# apollo3p register map
Vendor: Ambiq Micro; Series: Apollo; File version: 1.0
CPU: CM4 r1p0, little endian, MPU, FPU, I-cache, D-cache, VTOR, ITCM, DTCM, 3 interrupt priority bits, 0 interrupts
Registers are 32-bit, read-write, reset 0x0 unless marked. A register's access mark holds for its fields unless they carry their own. Offsets are from the block's base; [hi:lo] are bit positions.

## RTC — Real Time Clock
Base 0x40004200
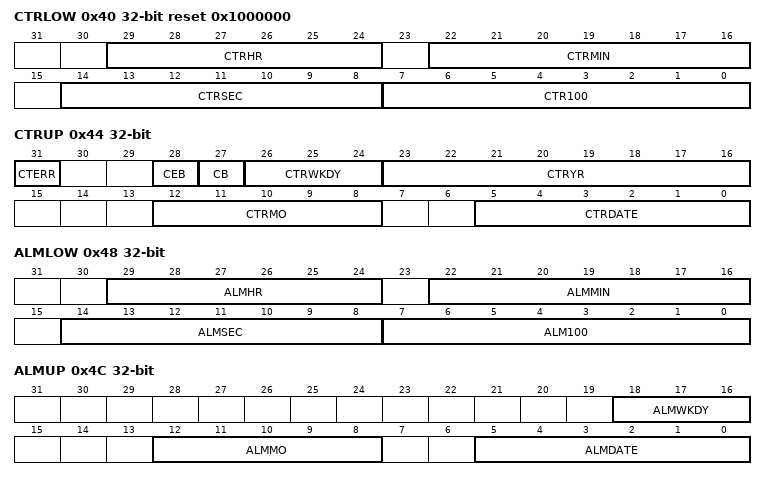
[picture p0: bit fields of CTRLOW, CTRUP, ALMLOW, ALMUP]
0x40 CTRLOW reset 0x1000000 — This counter contains the values for hour, minutes, seconds and 100ths of a second Counter.
  [29:24] CTRHR — Hours Counter
  [22:16] CTRMIN — Minutes Counter
  [14:8] CTRSEC — Seconds Counter
  [7:0] CTR100 — 100ths of a second Counter
0x44 CTRUP — This register contains the day, month and year information. It contains which day in the week, and the century as well. The information of the century can also be derived from the year information. The 31st bit contains the error bit. See description in the register bit for condition when error is triggered.
  [31] CTERR — Counter read error status. Error is triggered when software reads the lower word of the counters, and fails to read the upper counter within 1/100 second. This is because when the lower counter is read, the upper counter is held off from incrementing until it is read so that the full time stamp can be read.
    0=NOERR (No read error occurred); 1=RDERR (Read error occurred)
  [28] CEB — Century Enable Bit.
    0=DIS (Disable the Century bit from changing); 1=EN (Enable the Century bit to change)
  [27] CB — Century Bit. This bit will be toggled when the Years register rolls over from 99 to 00 if the CEB bit is a 1. CB=0 assumes the century it 19xx or 21xx, and CB=1 assumes it is 20xx for leap year calculations.
    0=Century is 2000s; 1=1900_2100 (Century is 1900s/2100s)
  [26:24] CTRWKDY — Weekdays Counter
  [23:16] CTRYR — Years Counter
  [12:8] CTRMO — Months Counter
  [5:0] CTRDATE — Date Counter
0x48 ALMLOW — This register is the Alarm settings for hours, minutes, second and 1/100th seconds settings.
  [29:24] ALMHR — Hours Alarm
  [22:16] ALMMIN — Minutes Alarm
  [14:8] ALMSEC — Seconds Alarm
  [7:0] ALM100 — 100ths of a second Alarm
0x4C ALMUP — This register is the alarm settings for week, month and day.
  [18:16] ALMWKDY — Weekdays Alarm
  [12:8] ALMMO — Months Alarm
  [5:0] ALMDATE — Date Alarm
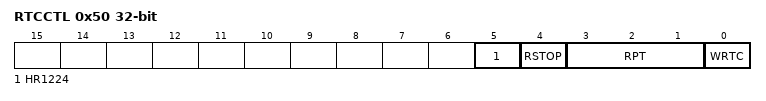
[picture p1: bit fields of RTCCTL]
0x50 RTCCTL — This is the register control for the RTC module. It sets the 12 or 24 hours mode, enables counter writes and sets the alarm repeat interval.
  [5] HR1224 — Hours Counter mode
    0=24HR (Hours in 24 hour mode); 1=12HR (Hours in 12 hour mode)
  [4] RSTOP — RTC input clock control
    0=RUN (Allow the RTC input clock to run); 1=STOP (Stop the RTC input clock)
  [3:1] RPT — Alarm repeat interval
    0=DIS (Alarm interrupt disabled); 1=YEAR (Interrupt every year); 2=MONTH (Interrupt every month); 3=WEEK (Interrupt every week); 4=DAY (Interrupt every day); 5=HR (Interrupt every hour); 6=MIN (Interrupt every minute); 7=SEC (Interrupt every second/10th/100th)
  [0] WRTC — Counter write control
    0=DIS (Counter writes are disabled); 1=EN (Counter writes are enabled)
0x100 INTEN — Set bits in this register to allow this module to generate the corresponding interrupt.
  [0] ALM — RTC Alarm interrupt
0x104 INTSTAT — Read bits from this register to discover the cause of a recent interrupt.
  [0] ALM — RTC Alarm interrupt
0x108 INTCLR — Write a 1 to a bit in this register to clear the interrupt status associated with that bit.
  [0] ALM — RTC Alarm interrupt
0x10C INTSET — Write a 1 to a bit in this register to instantly generate an interrupt from this module. (Generally used for testing purposes).
  [0] ALM — RTC Alarm interrupt

## SCARD — Serial ISO7816
Base 0x40080000
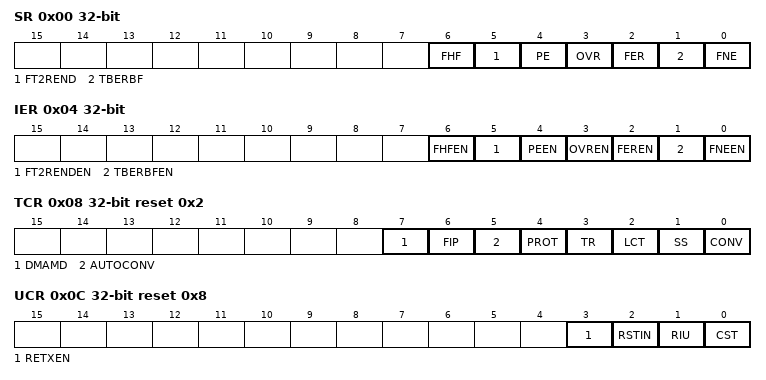
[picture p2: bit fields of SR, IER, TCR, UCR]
0x00 SR — ISO7816 interrupt status
  [6] FHF — FIFO Half Full.
    1=HALFFULL (FIFO is half full.)
  [5] FT2REND — TX to RX finished.
    1=CMPL (TX to RX completed.); 0=NOTCMPL (TX to RX not completed.)
  [4] PE — Parity Error.
    1=PEERR (Parity error.); 0=PENONE (No parity error.)
  [3] OVR — RX FIFO overflow.
    1=RXOVR (RX FIFO overflow.); 0=RXOVRNONE (RX FIFO no overflow.)
  [2] FER — Framing error.
    1=FRAMINGERR (Framing error.); 0=NOFRAMINGERR (No framing error detected.)
  [1] TBERBF — FIFO empty (transmit) or full (receive).
    1=TXFIFOEMPTY (Transmit: FIFO empty.); 0=TXFIFONOTEMPTY (Transmit: FIFO not empty.)
  [0] FNE — RX FIFO not empty.
    1=NOTEMPTY (RX FIFO not empty.); 0=EMPTY (RX FIFO empty.)
0x04 IER — ISO7816 interrupt enable
  [6] FHFEN — FIFO Half Full interrupt enable.
  [5] FT2RENDEN — TX to RX finished interrupt enable.
  [4] PEEN — Parity Error interrupt enable.
  [3] OVREN — RX FIFOI overflow interrupt enable.
  [2] FEREN — Framing error interrupt enable.
  [1] TBERBFEN — FIFO empty (transmit) or full (receive) interrupt enable.
  [0] FNEEN — RX FIFO not empty interrupt enable.
0x08 TCR reset 0x2 — ISO7816 transmit control
  [7] DMAMD — DMA direction.
  [6] FIP — Parity select.
  [5] AUTOCONV — Automatic conversion.
  [4] PROT — PROT control.
  [3] TR — Transmit/receive mode.
  [2] LCT — Fast TX to RX.
  [1] SS — Use first byte to configure conversion.
  [0] CONV — Conversion inversion control.
0x0C UCR reset 0x8 — ISO7816 user control
  [3] RETXEN — Enable TX/RX time configuration.
  [2] RSTIN — Reset polarity.
  [1] RIU — ISO7816 reset. This bit is write-only.
  [0] CST — Clock control.
0x10 DR — ISO7816 data
  [7:0] DR — Data register.
0x14 BPRL reset 0x74 — ISO7816 baud rate low
  [7:0] BPRL — Baud rate low
0x18 BPRH reset 0x1 — ISO7816 baud rate high
  [3:0] BPRH — Baud rate high
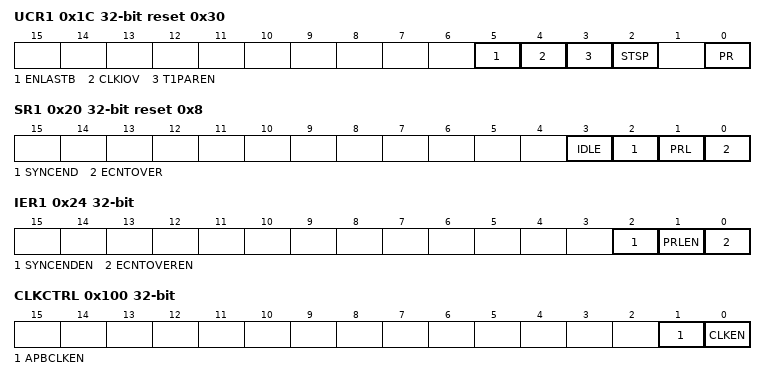
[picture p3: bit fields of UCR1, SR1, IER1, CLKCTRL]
0x1C UCR1 reset 0x30 — ISO7816 user control 1
  [5] ENLASTB — Enable last byte function.
  [4] CLKIOV — Output clock level.
  [3] T1PAREN — Parity check control.
  [2] STSP — ETU counter control. This bit is write-only.
  [0] PR — Query Card Detect.
0x20 SR1 reset 0x8 — ISO7816 interrupt status 1
  [3] IDLE — ISO7816 idle.
    1=IDLE (ISO7816 idle.); 0=ACTIVE (ISO7816 active.)
  [2] SYNCEND — Write complete synchronization.
    1=CMPL (Synchronization complete.); 0=INCMPL (Incomplete.)
  [1] PRL — Card insert/remove.
    1=INSREM (Card inserted/removed.)
  [0] ECNTOVER — ETU counter overflow.
    1=OVR (ETU overflow.)
0x24 IER1 — ISO7816 interrupt enable 1
  [2] SYNCENDEN — Write complete synchronization interrupt enable.
  [1] PRLEN — Card insert/remove interrupt enable.
  [0] ECNTOVEREN — ETU counter overflow interrupt enable.
0x28 ECNTL — ETU counter low
  [7:0] ECNTL — ETU counter low register.
0x2C ECNTH — ETU counter high
  [7:0] ECNTH — ETU counter high register.
0x30 GTR reset 0xFF — ISO7816 guard time configuration
  [7:0] GTR — Guard time configuration register.
0x34 RETXCNT reset 0x4 — ISO7816 resend count
  [3:0] RETXCNT — Resend count register.
0x38 RETXCNTRMI — ISO7816 resent count inquiry
  [3:0] RETXCNTRMI — Resent count inquiry register.
0x100 CLKCTRL — SCARD external clock control
  [1] APBCLKEN — Enable the SCARD APB clock to run continuously.
  [0] CLKEN — Enable the serial source clock for SCARD.
